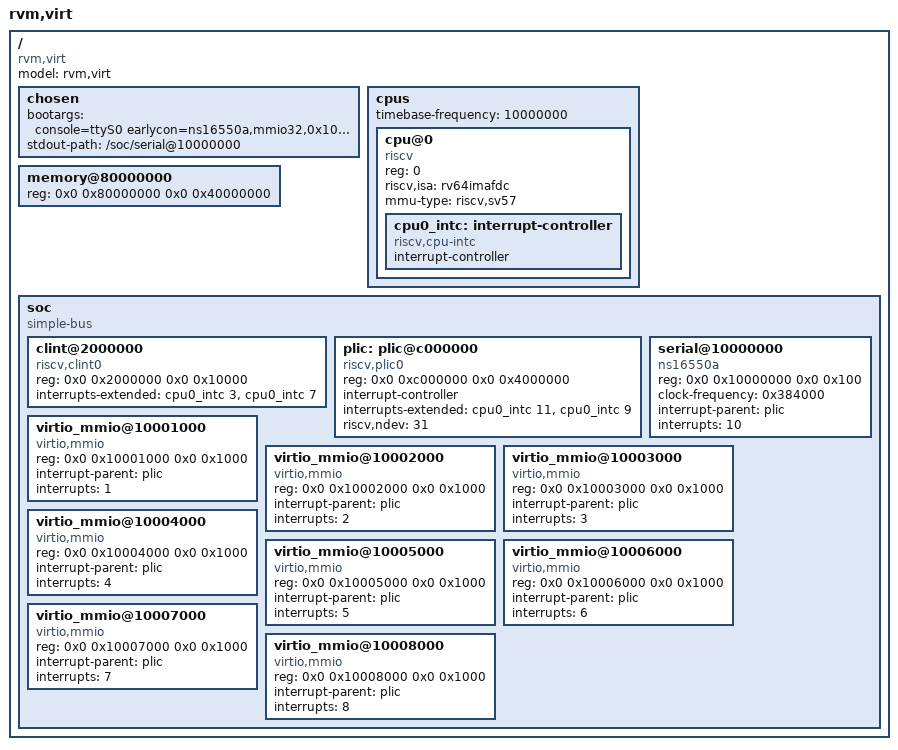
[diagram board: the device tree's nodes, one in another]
/dts-v1/;

/ {
	#address-cells = <2>;
	#size-cells = <2>;
	compatible = "rvm,virt";
	model = "rvm,virt";

	chosen {
		bootargs = "console=ttyS0 earlycon=ns16550a,mmio32,0x10000000 root=/dev/vda rootwait rw init=/bin/sh";
		stdout-path = "/soc/serial@10000000";
	};

	cpus {
		#address-cells = <1>;
		#size-cells = <0>;
		timebase-frequency = <10000000>;

		cpu@0 {
			device_type = "cpu";
			reg = <0>;
			status = "okay";
			compatible = "riscv";
			riscv,isa = "rv64imafdc";
			mmu-type = "riscv,sv57";

			cpu0_intc: interrupt-controller {
				#interrupt-cells = <1>;
				interrupt-controller;
				compatible = "riscv,cpu-intc";
			};
		};
	};

	memory@80000000 {
		device_type = "memory";
		reg = <0x0 0x80000000 0x0 0x40000000>;
	};

	soc {
		#address-cells = <2>;
		#size-cells = <2>;
		compatible = "simple-bus";
		ranges;

		clint@2000000 {
			compatible = "riscv,clint0";
			reg = <0x0 0x2000000 0x0 0x10000>;
			interrupts-extended = <&cpu0_intc 3 &cpu0_intc 7>;
		};

		plic: plic@c000000 {
			compatible = "riscv,plic0";
			reg = <0x0 0xc000000 0x0 0x4000000>;
			#interrupt-cells = <1>;
			#address-cells = <0>;
			interrupt-controller;
			interrupts-extended = <&cpu0_intc 11 &cpu0_intc 9>;
			riscv,ndev = <31>;
		};

		serial@10000000 {
			compatible = "ns16550a";
			reg = <0x0 0x10000000 0x0 0x100>;
			clock-frequency = <0x384000>;
			interrupt-parent = <&plic>;
			interrupts = <10>;
		};

		virtio_mmio@10001000 {
			compatible = "virtio,mmio";
			reg = <0x0 0x10001000 0x0 0x1000>;
			interrupt-parent = <&plic>;
			interrupts = <1>;
		};
		virtio_mmio@10002000 {
			compatible = "virtio,mmio";
			reg = <0x0 0x10002000 0x0 0x1000>;
			interrupt-parent = <&plic>;
			interrupts = <2>;
		};
		virtio_mmio@10003000 {
			compatible = "virtio,mmio";
			reg = <0x0 0x10003000 0x0 0x1000>;
			interrupt-parent = <&plic>;
			interrupts = <3>;
		};
		virtio_mmio@10004000 {
			compatible = "virtio,mmio";
			reg = <0x0 0x10004000 0x0 0x1000>;
			interrupt-parent = <&plic>;
			interrupts = <4>;
		};
		virtio_mmio@10005000 {
			compatible = "virtio,mmio";
			reg = <0x0 0x10005000 0x0 0x1000>;
			interrupt-parent = <&plic>;
			interrupts = <5>;
		};
		virtio_mmio@10006000 {
			compatible = "virtio,mmio";
			reg = <0x0 0x10006000 0x0 0x1000>;
			interrupt-parent = <&plic>;
			interrupts = <6>;
		};
		virtio_mmio@10007000 {
			compatible = "virtio,mmio";
			reg = <0x0 0x10007000 0x0 0x1000>;
			interrupt-parent = <&plic>;
			interrupts = <7>;
		};
		virtio_mmio@10008000 {
			compatible = "virtio,mmio";
			reg = <0x0 0x10008000 0x0 0x1000>;
			interrupt-parent = <&plic>;
			interrupts = <8>;
		};
	};
};
